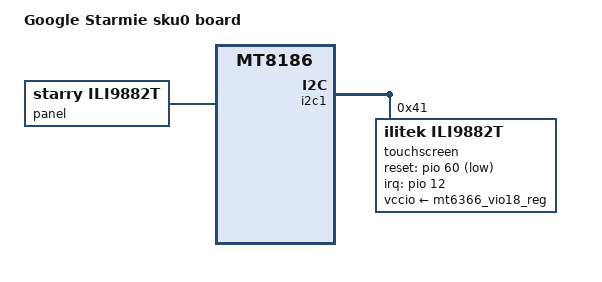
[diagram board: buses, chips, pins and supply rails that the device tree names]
// SPDX-License-Identifier: (GPL-2.0 OR MIT)
/*
 * Copyright 2023 Google LLC
 */

/dts-v1/;
#include "mt8186-corsola-starmie.dtsi"

/ {
	model = "Google Starmie sku0 board";
	compatible = "google,starmie-sku0", "google,starmie-sku2",
		     "google,starmie-sku3", "google,starmie",
		     "mediatek,mt8186";
};

&panel {
	compatible = "starry,ili9882t";
};

&i2c1 {
	touchscreen: touchscreen@41 {
		compatible = "ilitek,ili9882t";
		reg = <0x41>;
		interrupts-extended = <&pio 12 IRQ_TYPE_LEVEL_LOW>;
		pinctrl-names = "default";
		pinctrl-0 = <&touchscreen_pins>;
		panel = <&panel>;
		reset-gpios = <&pio 60 GPIO_ACTIVE_LOW>;
		vccio-supply = <&mt6366_vio18_reg>;
	};
};
